# UFS0_COMMON_0_P2A_WRAP_CFG_VBP_UFSHCI register map
Vendor: Texas Instruments
Registers are 32-bit, read-write, reset 0x0 unless marked. A register's access mark holds for its fields unless they carry their own. Offsets are as the file gives them; [hi:lo] are bit positions; lines under a group give offsets from that group; {n}, {i} and the like mark numbered series; 'fields as' and 'values as' point back to an identical list.

## UFS0_COMMON_0_P2A_WRAP_CFG_VBP_UFSHCI (part 2 of 2)
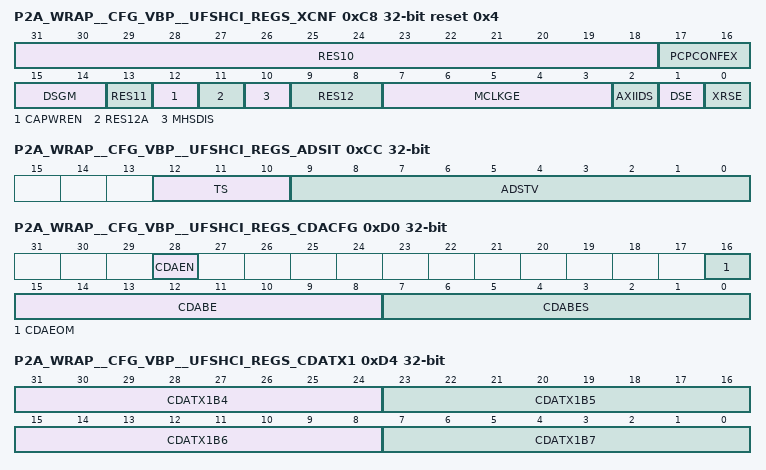
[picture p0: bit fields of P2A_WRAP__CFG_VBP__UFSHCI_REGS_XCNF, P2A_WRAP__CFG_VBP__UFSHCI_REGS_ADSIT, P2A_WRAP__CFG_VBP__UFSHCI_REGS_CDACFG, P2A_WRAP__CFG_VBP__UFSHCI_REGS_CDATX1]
0xC8 P2A_WRAP__CFG_VBP__UFSHCI_REGS_XCNF access per field reset 0x4
  [31:18] RES10 ro — RES - Reserved
  [17:16] PCPCONFEX rw — PCPCONFEX - Peer C-Port Configuration Extended These bits configure the peer C-Port configuration. 00b - Standard, no action 01b - Standard, no action 10b - Peer C-Port 0 connection state polling 11b - Peer configuration by UFSHCI
  [15:14] DSGM rw — DSGM - Deep-Sleep Generation Mode These bits define, how and when the {MK2,MK2} pattern is sent by the UFS host controller. 00b - Disabled. Regardless of the XCNF.DSE setting, no {MK2,MK2} pattern is generated. 01b - Use XCNF.DSE bit, static assignment. With this setting, the {MK2,MK2} pattern will be generated every time the TX path at the end of every data traffic, e.g. when the data path has no more data to send. Although this setting will generate the required {MK2,MK2} sequence, the {MK2,MK2} pattern is generated too often and unnecessary guard time delays appear in the system. 10b - Use ADSIT and XCNF.DSE With this setting, the {MK2,MK2} pattern will be send after the auto-deep-sleep counter is expired. The method how the {MK2,MK2} pattern is sent, is via 0-byte payload, e.g. at the end of the data transfer. This method also works when the device has not send a {MK2,MK2} with the final AFC. 11b - Use ADSIT and XCNF.DSE With this setting the, {MK2,MK2} pattern will be send after the auto-deep-sleep counter is expired. The method how the {MK2,MK2} pattern is send is via assertion of the UniPro burst signal, e.g. filler pattern. This method will not work if the device has not sent the {MK2,MK2} pattern yet, as there are AFCs going back as a response to a filler sequence. The deep-sleep mode defines the way, how and when the {MK2,MK2} pattern will be generated. The LA_TxLastMessage setting is taken from the XCNF.DSE bit.
  [13] RES11 ro — RES - Reserved
  [12] CAPWREN rw — CAPWREN - Capability Register Write Enable Setting this bit, will change the JEDEC capability register to be writable. 0h - Default behavior. Capability register is read only. 1h - Capability register can be written. This function can be used to verify different driver behavior. This is typically a debug feature and the register is most likely fixed in a production release.
  [11] RES12A ro — RES - Reserved
  [10] MHSDIS rw
  [9:8] RES12 ro — RES - Reserved
  [7:3] MCLKGE rw — MCLKGE - Module Clock Gating Enable These bits enable or disable the hierarchical clock gating per module. //[8] - UM support module clock gating enable/disable. [7] - OCS status word write module clock gating enable/disable. [6] - Read DMA data path module clock gating enable/disable. [5] - Write DMA data path module clock gating enable/disable. [4] - Command processing module clock gating enable/disable. [3] - Command fetching module clock gating enable/disable. All enable/disable bits follow the logic: 0b - Hierarchical clock gating enabled. 1b - Hierarchical clock gating disabled. The clocks are disabled at the individual module or function hierarchical boundary, based on internal status information, e.g. the 'OCS status word write module' will not be clocked whenever there is no status word to be written.
  [2] AXIIDS rw — AXIIDS - AXI ID support 0b - AXI ID support is disabled. 1b - AXI ID support is enabled.
  [1] DSE rw — DSE - Deep Sleep Enable This bit enables the extended {MK2,MK2} pattern generation. This extension is a MIPI UniPro features which allows saving power in the MPHY by turning off part of the MPHYs RX/TX logic - assuming that host and device are supporting deep-sleep. This happens transparent from the rest of the UFS system - unlike hibernate enter/exit which requires either host controller or software interaction. Internally, this bit is connected to the LA_TxLastMessage port of the UniPro IP, thus it allows for a static setting of the port. 0b - LA_LastMessage is de-asserted. No last message is generated based on the setting in the XCNF register fields. Sending a {MK2,MK2} pattern is still possible by using the MMTR register. 1b - LA_LastMessage is asserted. The {MK2,MK2} pattern is sent in the mode defined in the XCNF.DSGM field. Setting this bit to '0x1' and XCNF.DSGM to '0x01' will always send a {MK2,MK2} pattern after the data transmission is complete. Depending on the traffic pattern, this may introduce additional guard time delay on the link.
  [0] XRSE rw — XRSE - Extended Register Space Enable This bit enables the extended register space. This register space is located directly on top of the JEDEC defined UFSHCI register addresses. 0b - Extended Register Space not enabled. 1b - Extended Register Space enabled. Before enabling the pseudo error register space, the XASB.XDP register field has to be configured with the correct base address.
0xCC P2A_WRAP__CFG_VBP__UFSHCI_REGS_ADSIT
  [12:10] TS — TS - Time Scale Multiply value to increase count time 000: Value times 1 us 001: Value times 10 us 010: Value times 100 us 011: Value times 1 ms 100: Value times 10 ms 101: Value times 100 ms 110-111: Reserved.
  [9:0] ADSTV — ADSTV - Auto-Deep-Sleep Idle Timer Value This is the time that UFS subsystem must be idle before the UFS host controller may put the UFS link into deep-sleep state autonomously. The idle timer value is multiplied by the indicated timer scale to yield an absolute timer value. The idle timer starts decrement when all of the following conditions are satisfied: - UTRLDBR='0' - UTMRLDBR='0' - No UIC commanding is outstanding The idle timer shall continue decrement until it reaches zero or it is stopped as result of software access to one of host controller interface registers. When idle timer changes a non-zero to zero, the host controller shall put the UFS link into deep-sleep state. The host controller reloads this value each time the UFS link transitions out of the deep-sleep state. Software writes '0' to disable Auto-Deep-Sleep Idle Timer. Any non-zero value will enable Auto-Deep-Sleep idle timer. The minimum counter value is 1us, the maximum counter value is 102.3s. The Auto-Deep-Sleep idle timer will trigger the generation of the {MK2,MK2} transfer. The method, how the {MK2,MK2} pattern is generated is defined in the XCFN.DSGM register: 00b - Disabled. Setting this value will suppress any {MK2,MK2} pattern generation. Expiration of the auto-deep-sleep timer will have no effect. 01b - Use XCNF.DSE bit, static assignment. Expiration of the auto-deep-sleep timer will have no effect, e.g. there will be no activity. 10b - Use ADSIT. With this setting the {MK2,MK2} pattern will be send after the auto-deep-sleep counter has expired. The method how the {MK2,MK2} pattern is send is via 0-byte payload. 11b - Use ADSIT. With this setting the {MK2,MK2} pattern will be send after the auto-deep-sleep counter has expired. The method how the {MK2,MK2} pattern is send is via assertion of the UniPro burst signal.
0xD0 P2A_WRAP__CFG_VBP__UFSHCI_REGS_CDACFG access per field
  [28] CDAEN rw — CDAEN - C-Port Direct Access Enable This bit enables the direct access feature.
  [16] CDAEOM rw — CDAEOM - C-Port Direct Access End of message indicator. Setting this bit forces the Host UniPro adapter to flush the message.
  [15:8] CDABE rw — CDABE - C-Port Direct Access Byte Enables Byte enables for the transmit data. Bit 15: CDATX2B0 Bit 14: CDATX2B1 Bit 13: CDATX2B2 Bit 12: CDATX2B3 Bit 11: CDATX1B4 Bit 10: CDATX1B5 Bit 9: CDATX1B6 Bit 8: CDATX1B7 If not all bytes carry valid payload, valid bytes shall use the lower CDATXx byte fields. Example [Supported]: CDABE = FCh Example [Not supported]: CDABE = CFh
  [7:0] CDABES ro — CDABES - C-Port Direct Access Shadow Byte Enables Reserved for 64-bit data bus setup. In a 128bit system setup this field specifies the byte enables for the 64bit shadow register. Byte enables for the transmit data. Bit 15: CDATX2B0 shadow Bit 14: CDATX2B1 shadow Bit 13: CDATX2B2 shadow Bit 12: CDATX2B3 shadow Bit 11: CDATX1B4 shadow Bit 10: CDATX1B5 shadow Bit 9: CDATX1B6 shadow Bit 8: CDATX1B7 shadow If not all bytes carry valid payload, valid bytes shall use the lower CDATXx byte fields.
0xD4 P2A_WRAP__CFG_VBP__UFSHCI_REGS_CDATX1
  [63-8n:56-8n] CDATX1B{n} (n=4..7) — CDATX1B{n} - Write Data Byte {n}
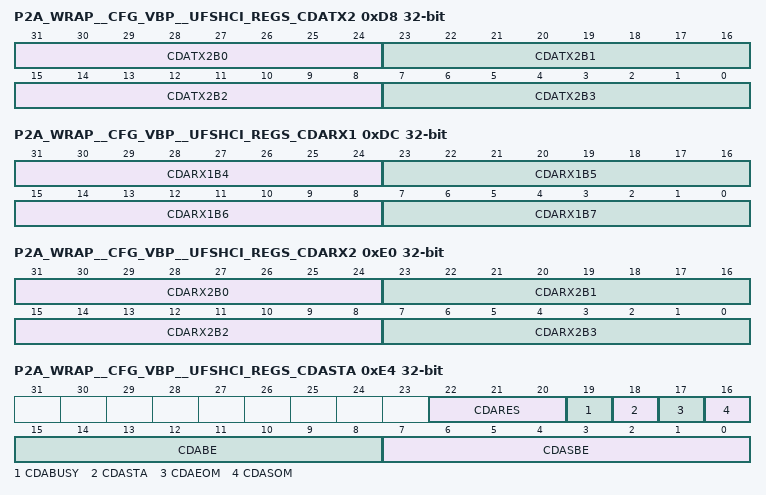
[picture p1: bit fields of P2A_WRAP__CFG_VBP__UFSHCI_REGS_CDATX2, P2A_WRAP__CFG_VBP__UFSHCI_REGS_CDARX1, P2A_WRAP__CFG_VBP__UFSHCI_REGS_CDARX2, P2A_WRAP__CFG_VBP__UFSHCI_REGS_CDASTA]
0xD8 P2A_WRAP__CFG_VBP__UFSHCI_REGS_CDATX2
  [31-8n:24-8n] CDATX2B{n} (n=0..3) — CDATX2B{n} - Write Data Byte {n}
0xDC P2A_WRAP__CFG_VBP__UFSHCI_REGS_CDARX1 ro
  [63-8n:56-8n] CDARX1B{n} (n=4..7) — CDARX1B{n} - Read Data Byte {n}
0xE0 P2A_WRAP__CFG_VBP__UFSHCI_REGS_CDARX2 ro
  [31-8n:24-8n] CDARX2B{n} (n=0..3) — CDARX2B{n} - Read Data Byte {n}
0xE4 P2A_WRAP__CFG_VBP__UFSHCI_REGS_CDASTA ro
  [22:20] CDARES — CDARES - C-Port Direct Access Result Transmit result code. This field stores the result information from the last transmit operation. This field carries the TxResultCode from the UIC layer. It becomes valid one HClk cycle after the transfer has been completed. 0: Access successful 1: local CPort is unconnected 2: reserved, unused for data transmission 3: local CPort is not available 6: peer device does not support selected TC 7: Message of 0 size rejected [EOM false]
  [19] CDABUSY — CDABUSY - C-Port Direct Access Busy This bit indicates whether the C-Port is busy. The software shall poll this bit and make sure that the C-Port is available prior to any write access to the CDATX1 or CDATX2 registers. During data transmission, this bit is set to 1 until the transfer has been completed. 0: C-Port available 1: C-Port busy
  [18] CDASTA — CDASTA - C-Port Direct Access Status The status bit indicates if there is new data in the buffer.
  [17] CDAEOM — CDAEOM - C-Port Direct Access EOM End of message indicator.
  [16] CDASOM — CDASOM - C-Port Direct Access SOM Start of message indicator
  [15:8] CDABE — CDABE - C-Port Direct Access Byte Enable Byte enable settings for the received data.
  [7:0] CDASBE — CDASBE - C-Port Direct Access Shadow Byte Enable Reserved in a 64 system bus configuration. In a 128 system bus configuration this field contains the byte enable settings for the received data in the shadow register.
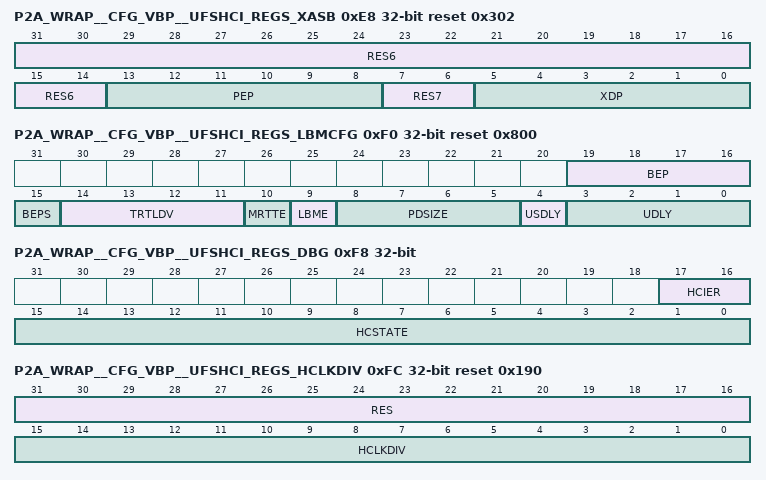
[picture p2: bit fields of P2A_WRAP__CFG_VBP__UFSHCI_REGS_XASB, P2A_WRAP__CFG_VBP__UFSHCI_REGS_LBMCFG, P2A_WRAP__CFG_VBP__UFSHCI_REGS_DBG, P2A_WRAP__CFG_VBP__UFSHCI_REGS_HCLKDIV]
0xE8 P2A_WRAP__CFG_VBP__UFSHCI_REGS_XASB access per field reset 0x302
  [31:14] RES6 ro — RES - Reserved
  [13:8] PEP rw — PEP - Pseudo Error Page This address defines define the page address for the pseudo error configuration and control register in units of 1Kbytes. Minimum value is 01h to avoid collisions with MMIO page. Available Register: - All pseudo error register The page address is only valid [and will be used for address selection] when the XCNF.PERSEN is set to '1'.
  [7:6] RES7 ro — RES - Reserved
  [5:0] XDP rw — XDP - Extended Debug Page This address defines the page address of the extended debugging information. Available registers: - EXTREG1 - ... - EXTREG8 - UFSDC - UPSTAT - URW - URS - CDC - RTDDC - TPTXF - TPRXF - IUE - MMTR The page address is only valid [and will be used for address selection] when the XCNF.XRSE is set to '1'. All accesses to the Extended Debug Page will not wake up the host controller from auto-hibernate or auto deep-sleep.
0xF0 P2A_WRAP__CFG_VBP__UFSHCI_REGS_LBMCFG reset 0x800
  [19:16] BEP — BEP - Byte Enable Pattern This field defines the number of valid byte enables. The byte enables are filled up from MSB to LSB. This is a test mode only. For normal operation this field should be kept at the default value. 1 - Byte 7 enabled 2 - Byte 7:6 enabled 3 - Byte 7:5 enabled 4 - Byte 7:4 enabled 5 - Byte 7:3 enabled 6 - Byte 7:2 enabled 7 - Byte 7:1 enabled Others - Byte 7:0 enabled The field width is 4 bit in case the IP is configured for 64bit system data bus width and 5bit for a 128bit configuration.
  [15] BEPS — BEPS - Byte Enable Pattern Selection This bit selects between a random byte enable pattern and a fixed byte enable pattern in 'read only' mode [LUN 0]. In write only and 'loopback mode' this field is ignored. The fixed byte enable pattern is taken from the BEP field of the LBMCFG register. This is a test mode only. For normal operation this field should be kept at the default value. 0b - Fixed byte enable pattern taken from BEP field 1b - Random byte enable pattern
  [14:11] TRTLDV — TRTLDV - Throttle Divide Since the bandwidth on the system bus may be much higher than actually supported by the UniPro link, this value allows to throttle the bandwidth in order to better mimic a real UFS Device. However, by this, some inaccuracy to the performance measurement will be introduced since the time to fill or empty the system bus buffer changes, which in turn has influence on the rate in which system bus requests to the bus fabric can be issued. Value 0: Reserved Value 1-15: Divide the frequency in which data is requested from the system bus RX buffer and/or stored into the system bus TX buffer.
  [10] MRTTE — MRTTE - Multi RTT Enable This bit enables the multiple RTT feature. Here multiple RTT may be submitted by the loopback logic. This feature tests the performance of back to back DATAOUT UPIUs. It provides feedback about the capabilities of the host controller RTT management capabilities. If DATAOUT UPIUs exceed a certain size [size depends on the access latency to the system memory], a second outstanding RTT may help reducing the latency between two consecutive DATAOUT UPIUs. This feature requires that a second RTT is send to the host controller ahead of time. This enables the data management to fetch the data for the second RTT, while the data for the first RTT is still being sent over the UniPro link. It should be noted, that data transfer is in-order, and thus sending of data which belongs to the second RTT will not start before the first RTT is completely handled. The maximum number of outstanding RTT is two. Once the DATAOUT UPIUs for both RTTs have been transmitted, the next RTTs [2 or less] will be issued until all data that have been requested by the SCSI command were transferred. 0: Only one RTT 1: Up to two outstanding RTTs
  [9] LBME — LBME - Loopback Enable bit Setting this bit decouples the UniPro layer from the host controller logic and switches the input data stream to take packets from the loopback logic. If LBME=0, the UPIU loopback circuit is in reset. If LBME=1, it is assured that no interaction with an attached UFS Device takes place.
  [8:5] PDSIZE — PDSIZE - Data Size This value is a 4-bit field and defines the amount of the data that will be requested by the RTT. This mimics the ability of the UFS Device to limit the size of a DATAOUT UPIU. In loopback mode, PDSIZE defines the size of DATAOUT and DATAIN UPIUs. The field should be interpreted as the exponent of the function pow[2, PDSIZE+1]. PDSIZE values from 3h to Eh are supported. This allows sizes from 16 to 32768 bytes.
  [4] USDLY — USDLY - UPIU Source Delay This one-bit field defines whether there is a delay before every RTTs or DATAIN packet or just before the first one.
  [3:0] UDLY — UDLY - UPIU Delay This value is a 4-bit field and defines the delay [in clock cycles] from receiving the command till the response is send back to the host controller. The response could either be an RTT UPIU or a DATAIN UPIU. This allows the host controller to fetch the required PRD entries an immediately continue with processing the RTT or DATAIN UPIU. The field should be interpreted as the exponent of the function pow[2, UDLY+4]. This allows delays from 16 to 524288 clock cycles which is approx. from 80ns to 2.6ms with a 200MHz clock. Those large numbers mimic the real behaviour of current devices. A value of zero disables this feature, means no delay. Whether or not this delay is used for every return packet or just for the first one is controlled by the USDLY field.
0xF4 P2A_WRAP__CFG_VBP__UFSHCI_REGS_LBMSTA ro
  [0] ERR — ERR - Error Indicator Indicates that there is general error. ERR=1 indicates that an error condition has been detected. Once an error condition has been detected, the UPIU loopback circuit needs to be disabled and enabled again via the LBME bit. By this, the ERR register is cleared. Detectable error conditions: Command sent to unsupported LUN Unsupported command [Transaction Type]
0xF8 P2A_WRAP__CFG_VBP__UFSHCI_REGS_DBG ro
  [17:16] HCIER — HCIER - Host Controller Internal Error Register This register displays host controller internal errors which are not covered by the JEDEC official errors reported back via the OCS value. 0h: No error occurred 1h: No valid TAG/LUN combination found. The UPIU with no valid TAG/LUN combination will be silently discarded. 2h: No valid TAG/LUN/IID combination found. The UPIU with no valid TAG/LUN/IID combination will be silently discarded.
  [15:0] HCSTATE — HCSTATE - Host Controller State Register These bits indicate the internal state of the host controller. The value is used for internal use only. 0h: No error occurred value: An error occurred. The meaning of the value is not disclosed.
0xFC P2A_WRAP__CFG_VBP__UFSHCI_REGS_HCLKDIV access per field reset 0x190
  [31:16] RES ro — RES - Reserved
  [15:0] HCLKDIV rw — HCLKDIV - HClock Divide HCLKDIV = HCLKFrequency [MHz] The default value of the HCLKDIV register assumes a HClk frequency of 400MHz. The default value may be adjusted during implementation by changing the P_P_CLKDIV parameter.
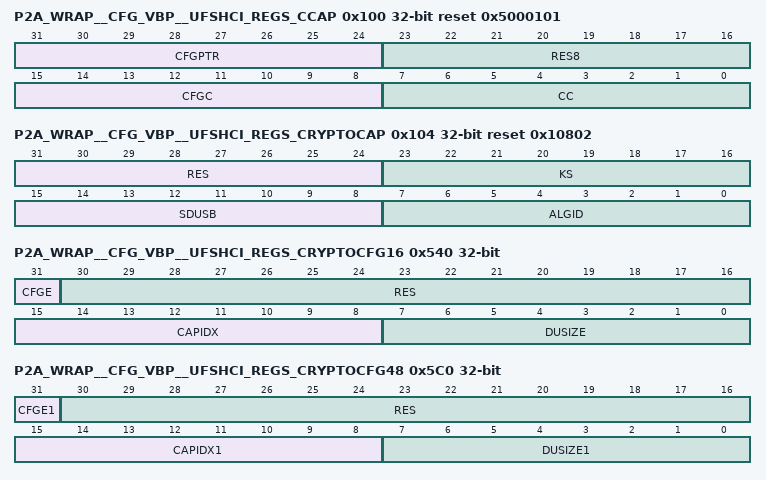
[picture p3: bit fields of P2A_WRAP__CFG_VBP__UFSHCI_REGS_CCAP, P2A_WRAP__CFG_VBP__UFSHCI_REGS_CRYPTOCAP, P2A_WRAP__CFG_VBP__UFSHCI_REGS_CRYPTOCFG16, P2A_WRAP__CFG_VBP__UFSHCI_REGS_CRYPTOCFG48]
0x100 P2A_WRAP__CFG_VBP__UFSHCI_REGS_CCAP ro reset 0x5000101
  [31:24] CFGPTR — CFGPTR - Configuration Array Pointer An offset pointer to the base of the Configuration Array [X-CRYPTOCFG registers], in 256B units. CFGPTR value shall be larger than 04h, so it does not conflict with a maximum size X-CRYPTOCAP array. The address for entry x of the X-CRYPTOCFG array is calculated as follows: ADDR [X-CRYPTOCFG] = CFGPTR*100h + x*80h, with x in [0..CCAP.CFGC] and x derived from UTRD.CCI field.
  [23:16] RES8 — RES - Reserved
  [15:8] CFGC — CFGC - Configuration Count The maximum number of configurations supported by the host controller. The actual number of configurations is equal to [CFGC+1]. The minimum number of configurations supported is 1 [CFGC=00h]. The maximum number of configurations supported is 256 [CFGC=FFh].
  [7:0] CC — CC - Crypto Capabilities The number of crypto capabilities that the host controller provides. The values allowed are between 1 and 255[the limit on the number of crypto capabilities].
0x104 P2A_WRAP__CFG_VBP__UFSHCI_REGS_CRYPTOCAP ro reset 0x10802
  [31:24] RES — RES - Reserved
  [23:16] KS — KS - Key Size Specifies the Key Size in bits used by this algorithm: 00h: Reserved 01h: 128bits 02h: 192bits [not supported] 03h: 256bits [not supported] 04h: 512bits [not supported] 05h-FFh: Reserved
  [15:8] SDUSB — SDUSB - Supported Data Unit Size Bitmask Specifies the data unit sizes supported by the capability, in bitmask encoding. When bit j in the field [j=0...7] is set, data unit size of 512*2^j bytes is supported. Supported values: 512B [j=0] through 64KB [j=7]. One bit or more in this field may be set. For example, if sizes 1KB, 4KB, and 16KB are supported by the capability, then SDUSB=00101010b [=2Ah].
  [7:0] ALGID — ALGID - Algorithm Identification code of the crypto algorithm according to the following table value: 00h: AES-XTS [not supported] 01h: Bitlocker-AES-CBC [not supported] 02h: AES-ECB 03h: ESSIV AES-CBC [not supported] 04h-7Fh: Reserved 80h-FFh: Vendor specific This register can only be accessed when the encryption feature is implemented [CAP.CS=1].
{0x500+4i} P2A_WRAP__CFG_VBP__UFSHCI_REGS_CRYPTOCFG{i} wo (i=0..3)
  [31:0] CRYPTOKEY{i} — CRYPTOKEY{i} - Crypto Key {i} Specifies the key to be used for this configuration. The specific key layout is defined according to the key size and algorithm specified in the Crypto Capability with index value specified in CAPIDX. When configuring CRYPTOKEY field software shall write the entire key sequentially, in one atomic set of operations. To regions of CRYPTOKEY which are unused, according to key size and algorithm selection, software shall write zeros.
0x540 P2A_WRAP__CFG_VBP__UFSHCI_REGS_CRYPTOCFG16 access per field
  [31] CFGE rw — CFGE - Configuration Enable This field is used by software to enable/disable a Crypto Configuration usage by software 0b: Configuration Disabled. Transaction using this Crypto Configuration in the UTRD.CCI field shall be terminated with error by host controller [OCS=INVALID_CRYPTO_CONFIG] 1b: Configuration Enabled. Transaction using this Configuration in the UTRD.CCI field can be executed.
  [30:16] RES ro — RES - Reserved
  [15:8] CAPIDX rw — CAPIDX - Crypto Capability Index Specifies the index of the Crypto Capability to be used for this configuration. Values allowed are between 0 and CCAP.CC-1. There is no hardware range check implemented.
  [7:0] DUSIZE rw — DUSIZE - Data Unit Size Size of data unit used with this configuration, one-hot encoded, analogous to bitmask used in CRYPTOCAP.SDUSB field. When bit j in this field [j=0...7] is set, a data unit size of 512*2^j bytes is selected. Bit j shall only be set if the same bit is also set in the SDUSB field og the capability referenced in CAPIDX field. There is no hardware check for consistency between CRYPTOCFG.DUSIZE and CRYPTOCAP.SDUSB.
0x544 P2A_WRAP__CFG_VBP__UFSHCI_REGS_CRYPTOCFG17
  [31:16] VSB — VSB - Vendor-Specific Bits This field is used by software to enable host-features associated with the Crypto Configuration.
{0x500+4i} P2A_WRAP__CFG_VBP__UFSHCI_REGS_CRYPTOCFG{i} wo (i=32..35)
  [31:0] CRYPTOKEY{i} — CRYPTOKEY{i} - Crypto Key {i-32} for second crypto configuration Specifies the key to be used for this configuration. The specific key layout is defined according to the key size and algorithm specified in the Crypto Capability with index value specified in CAPIDX. When configuring CRYPTOKEY field software shall write the entire key sequentially, in one atomic set of operations. To regions of CRYPTOKEY which are unused, according to key size and algorithm selection, software shall write zeros.
0x5C0 P2A_WRAP__CFG_VBP__UFSHCI_REGS_CRYPTOCFG48 access per field
  [31] CFGE1 rw — CFGE1 - Configuration Enable for second crypto configuration This field is used by software to enable/disable a Crypto Configuration usage by software 0b: Configuration Disabled. Transaction using this Crypto Configuration in the UTRD.CCI field shall be terminated with error by host controller [OCS=INVALID_CRYPTO_CONFIG] 1b: Configuration Enabled. Transaction using this Configuration in the UTRD.CCI field can be executed.
  [30:16] RES ro — RES - Reserved
  [15:8] CAPIDX1 rw — CAPIDX1 - Crypto Capability Index for second crypto configuration Specifies the index of the Crypto Capability to be used for this configuration. Values allowed are between 0 and CCAP.CC-1. There is no hardware range check implemented.
  [7:0] DUSIZE1 rw — DUSIZE1 - Data Unit Size for second crypto configuration Size of data unit used with this configuration, one-hot encoded, analogous to bitmask used in CRYPTOCAP.SDUSB field. When bit j in this field [j=0...7] is set, a data unit size of 512*2^j bytes is selected. Bit j shall only be set if the same bit is also set in the SDUSB field og the capability referenced in CAPIDX field. There is no hardware check for consistency between CRYPTOCFG.DUSIZE and CRYPTOCAP.SDUSB.
0x5C4 P2A_WRAP__CFG_VBP__UFSHCI_REGS_CRYPTOCFG49
  [31:16] VSB1 — VSB1 - Vendor-Specific Bits for second crypto configuration This field is used by software to enable host-features associated with the Crypto Configuration.
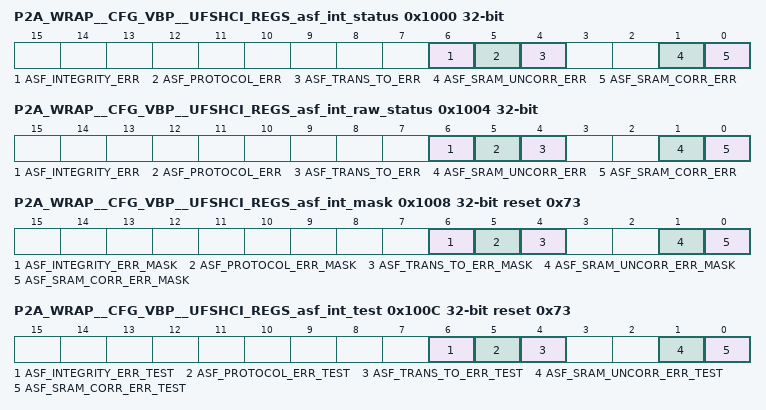
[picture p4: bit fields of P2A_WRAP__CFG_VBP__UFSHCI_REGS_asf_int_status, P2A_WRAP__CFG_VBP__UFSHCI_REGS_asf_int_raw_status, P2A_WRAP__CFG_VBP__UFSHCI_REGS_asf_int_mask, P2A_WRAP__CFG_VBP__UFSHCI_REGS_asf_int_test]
0x1000 P2A_WRAP__CFG_VBP__UFSHCI_REGS_asf_int_status access not given
  [6] ASF_INTEGRITY_ERR — Integrity error interrupt (access R/W1TC)
  [5] ASF_PROTOCOL_ERR — Protocol error interrupt (access R/W1TC)
  [4] ASF_TRANS_TO_ERR — Transaction timeouts error interrupt (access R/W1TC)
  [1] ASF_SRAM_UNCORR_ERR — SRAM uncorrectable error interrupt (access R/W1TC)
  [0] ASF_SRAM_CORR_ERR — SRAM correctable error interrupt (access R/W1TC)
0x1004 P2A_WRAP__CFG_VBP__UFSHCI_REGS_asf_int_raw_status access not given
  fields as P2A_WRAP__CFG_VBP__UFSHCI_REGS_asf_int_status
0x1008 P2A_WRAP__CFG_VBP__UFSHCI_REGS_asf_int_mask access not given reset 0x73
  [6] ASF_INTEGRITY_ERR_MASK rw — Mask bit for integrity error interrupt
  [5] ASF_PROTOCOL_ERR_MASK rw — Mask bit for protocol error interrupt.
  [4] ASF_TRANS_TO_ERR_MASK rw — Mask bit for transaction timeouts error interrupt.
  [1] ASF_SRAM_UNCORR_ERR_MASK rw — Mask bit for SRAM uncorrectable error interrupt.
  [0] ASF_SRAM_CORR_ERR_MASK rw — Mask bit for SRAM correctable error interrupt.
0x100C P2A_WRAP__CFG_VBP__UFSHCI_REGS_asf_int_test access not given reset 0x73
  [6] ASF_INTEGRITY_ERR_TEST wo — Test bit for integrity error interrupt
  [5] ASF_PROTOCOL_ERR_TEST wo — Test bit for protocol error interrupt.
  [4] ASF_TRANS_TO_ERR_TEST wo — Test bit for transaction timeouts error interrupt.
  [1] ASF_SRAM_UNCORR_ERR_TEST wo — Test bit for SRAM uncorrectable error interrupt.
  [0] ASF_SRAM_CORR_ERR_TEST wo — Test bit for SRAM correctable error interrupt.
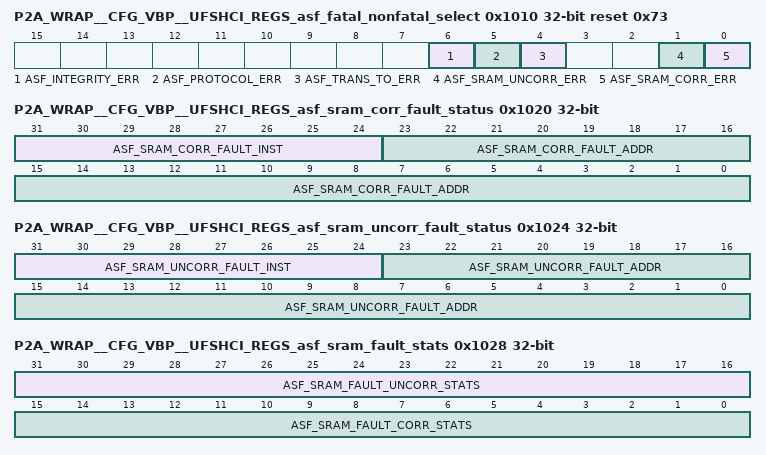
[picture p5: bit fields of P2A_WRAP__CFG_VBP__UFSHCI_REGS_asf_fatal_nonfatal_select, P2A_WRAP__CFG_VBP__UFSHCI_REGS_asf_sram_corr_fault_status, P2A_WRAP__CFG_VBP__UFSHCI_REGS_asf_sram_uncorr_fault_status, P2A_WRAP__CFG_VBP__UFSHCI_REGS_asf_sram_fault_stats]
0x1010 P2A_WRAP__CFG_VBP__UFSHCI_REGS_asf_fatal_nonfatal_select access not given reset 0x73
  [6] ASF_INTEGRITY_ERR rw — Enable integrity error interrupt as fatal
  [5] ASF_PROTOCOL_ERR rw — Enable protocol error interrupt as fatal.
  [4] ASF_TRANS_TO_ERR rw — Enable transaction timeouts error interrupt as fatal.
  [1] ASF_SRAM_UNCORR_ERR rw — Enable SRAM uncorrectable error interrupt as fatal.
  [0] ASF_SRAM_CORR_ERR rw — Enable SRAM correctable error interrupt as fatal.
0x1020 P2A_WRAP__CFG_VBP__UFSHCI_REGS_asf_sram_corr_fault_status ro
  [31:24] ASF_SRAM_CORR_FAULT_INST — This encoding indicates which SRAM Instance has a Correctable Fault. The encoding of the SRAM is as follow: Decimal Encoding - Instance Type - Description - Module Name 0 - RDF - Read Data FIFO - RDP 1 - RDC - Read Data Path Control Unit - RDC 2 - WDF - Write Data FIFO - WDP 3 - WDCF - Write Data Path Control FIFO - WDC 4 - WDC - Write Data Path Control Unit - WDC 5 - RTT - WDC RTT command stack - WDC 6 - WDCM - WDC task management command stack - WDC 7 - CIP - Command Interface Port - CIP 8 - CMU1 - Command Memmory Unit - CMU 9 - CMU2 - Command Memmory Unit - CMU 10 - CMU3 - Command Memmory Unit - CMU 11 - CMU4 - Command Memmory Unit - CMU 12 - CMU5 - Command Memmory Unit - CMU 13 - CMU6 - Command Memmory Unit - CMU 14 - CMU7 - Command Memmory Unit - CMU 15 - TMU - Task Management Unit - TMU 16 - UniPro L2RX - UniPro - L2TX 17* - UniPro L2TX - UniPro - L2RX 18* - UniPro L2TX - UniPro - L2RX 19 - CCI - Crypto Configuration Index - AES 20 - ID - Stores the identifiers for the selected Doorbell Register slot numbers - AES *NOTE: ID17 used for uncorrectable errors ID18 used for correctable errors.
  [23:0] ASF_SRAM_CORR_FAULT_ADDR — This indicates the address where the Correctable fault was observed.
0x1024 P2A_WRAP__CFG_VBP__UFSHCI_REGS_asf_sram_uncorr_fault_status ro
  [31:24] ASF_SRAM_UNCORR_FAULT_INST — This encoding indicates which SRAM Instance has a UnCorrectable Fault. The encoding of the SRAM is as follow: Decimal Encoding - Instance Type - Description - Module Name 0 - RDF - Read Data FIFO - RDP 1 - RDC - Read Data Path Control Unit - RDC 2 - WDF - Write Data FIFO - WDP 3 - WDCF - Write Data Path Control FIFO - WDC 4 - WDC - Write Data Path Control Unit - WDC 5 - RTT - WDC RTT command stack - WDC 6 - WDCM - WDC task management command stack - WDC 7 - CIP - Command Interface Port - CIP 8 - CMU1 - Command Memmory Unit - CMU 9 - CMU2 - Command Memmory Unit - CMU 10 - CMU3 - Command Memmory Unit - CMU 11 - CMU4 - Command Memmory Unit - CMU 12 - CMU5 - Command Memmory Unit - CMU 13 - CMU6 - Command Memmory Unit - CMU 14 - CMU7 - Command Memmory Unit - CMU 15 - TMU - Task Management Unit - TMU 16 - UniPro L2RX - UniPro - L2TX 17* - UniPro L2TX - UniPro - L2RX 18* - UniPro L2TX - UniPro - L2RX 19 - CCI - Crypto Configuration Index - AES 20 - ID - Stores the identifiers for the selected Doorbell Register slot numbers - AES *NOTE: ID17 used for uncorrectable errors ID18 used for correctable errors.
  [23:0] ASF_SRAM_UNCORR_FAULT_ADDR — This indicates the address where the UnCorrectable fault was observed.
0x1028 P2A_WRAP__CFG_VBP__UFSHCI_REGS_asf_sram_fault_stats access not given
  [31:16] ASF_SRAM_FAULT_UNCORR_STATS — Count of number of uncorrectable errors if implemented. Count value will saturate at 0xffff. (access R/W1TC)
  [15:0] ASF_SRAM_FAULT_CORR_STATS — Count of number of correctable errors if implemented. Count value will saturate at 0xffff. (access R/W1TC)
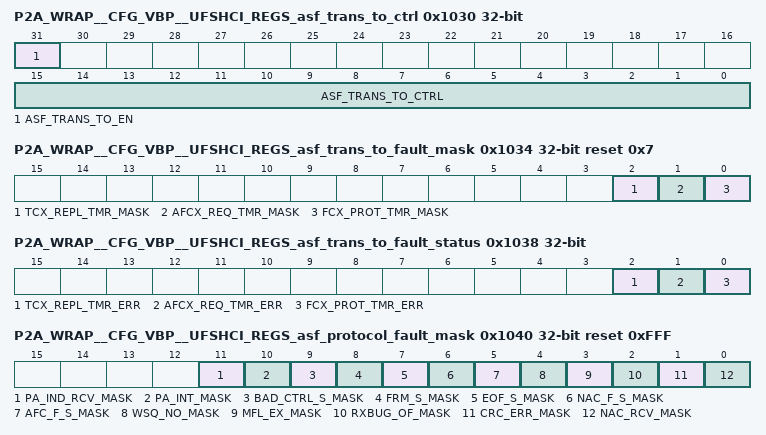
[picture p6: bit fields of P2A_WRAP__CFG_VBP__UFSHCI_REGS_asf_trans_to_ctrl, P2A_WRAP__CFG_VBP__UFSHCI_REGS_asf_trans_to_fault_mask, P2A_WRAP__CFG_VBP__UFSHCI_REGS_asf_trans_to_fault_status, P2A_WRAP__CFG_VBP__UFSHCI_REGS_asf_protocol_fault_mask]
0x1030 P2A_WRAP__CFG_VBP__UFSHCI_REGS_asf_trans_to_ctrl access not given
  [31] ASF_TRANS_TO_EN rw — Enable transaction timeout monitoring.
  [15:0] ASF_TRANS_TO_CTRL rw — Reserved.
0x1034 P2A_WRAP__CFG_VBP__UFSHCI_REGS_asf_trans_to_fault_mask access not given reset 0x7
  [2] TCX_REPL_TMR_MASK rw — TCx_REPLAY_TIMER_EXPIRED mask.
  [1] AFCX_REQ_TMR_MASK rw — AFCx_REQUEST_TIMER_EXPIRED mask.
  [0] FCX_PROT_TMR_MASK rw — FCx_PROTECTION_TIMER_EXPIRED mask.
0x1038 P2A_WRAP__CFG_VBP__UFSHCI_REGS_asf_trans_to_fault_status access not given
  [2] TCX_REPL_TMR_ERR — TCx_REPLAY_TIMER_EXPIRED timeout detected. The replay timer [TCx_REPLAY_TIMER, where x=0 or 1] guards against losing AFC or NAC Frame detection. (access R/W1TC)
  [1] AFCX_REQ_TMR_ERR — AFCx_REQUEST_TIMER_EXPIRED timeout detected. The Frame acknowledge timer [AFCx_REQUEST_TIMER] shall guarantee that the remote transmitter schedules an AFC Frame before the transmitter TCx_REPLAY_TIMER expires. (access R/W1TC)
  [0] FCX_PROT_TMR_ERR — FCx_PROTECTION_TIMER_EXPIRED timeout detected. The FCx_PROTECTION_TIMER id used for protecting against loss of credits due to the loss of the AFCx Frame. (access R/W1TC)
0x1040 P2A_WRAP__CFG_VBP__UFSHCI_REGS_asf_protocol_fault_mask access not given reset 0xFFF
  [11] PA_IND_RCV_MASK rw — When set to 1 disables the UniPro PA_ERROR_IND_RECEIVED.
  [10] PA_INT_MASK rw — When set to 1 disables the UniPro PA_INIT_ERROR.
  [9] BAD_CTRL_S_MASK rw — When set to 1 disables the UniPro BAD_CTRL_SYMBOL_TYPE.
  [8] FRM_S_MASK rw — When set to 1 disables the UniPro FRAME_SYNTAX_ERROR.
  [7] EOF_S_MASK rw — When set to 1 disables the UniPro EOF_SYNTAX_ERROR.
  [6] NAC_F_S_MASK rw — When set to 1 disables the UniPro NAC_FRAME_SYNTAX_ERROR.
  [5] AFC_F_S_MASK rw — When set to 1 disables the UniPro AFC_FRAME_SYNTAX_ERROR.
  [4] WSQ_NO_MASK rw — When set to 1 disables the UniPro WRONG_SEQUENCE_NUMBER.
  [3] MFL_EX_MASK rw — When set to 1 disables the UniPro MAX_FRAME_LENGTH_EXCEEDED.
  [2] RXBUG_OF_MASK rw — When set to 1 disables the UniPro RX_BUFFER_OVERFLOW.
  [1] CRC_ERR_MASK rw — When set to 1 disables the UniPro CRC_ERROR.
  [0] NAC_RCV_MASK rw — When set to 1 disables the UniPro NAC_RECEIVED.
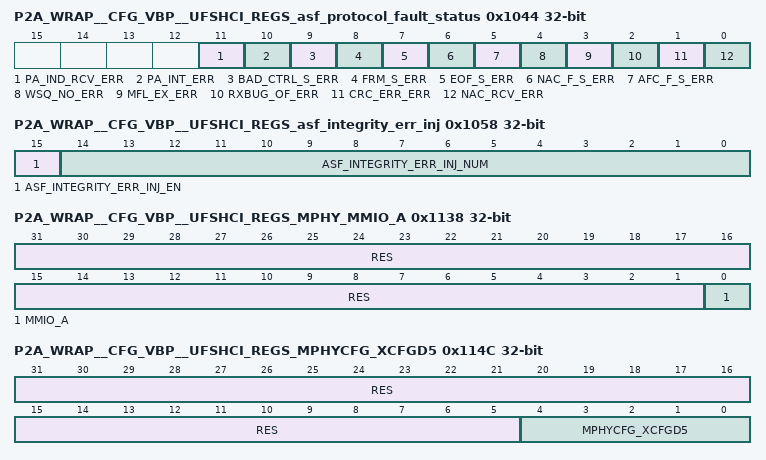
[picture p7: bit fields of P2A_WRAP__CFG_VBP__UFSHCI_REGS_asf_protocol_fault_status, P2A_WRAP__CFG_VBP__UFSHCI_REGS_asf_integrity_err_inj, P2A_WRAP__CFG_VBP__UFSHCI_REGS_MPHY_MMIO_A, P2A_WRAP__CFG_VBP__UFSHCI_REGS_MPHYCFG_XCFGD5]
0x1044 P2A_WRAP__CFG_VBP__UFSHCI_REGS_asf_protocol_fault_status access not given
  [11] PA_IND_RCV_ERR — UniPro PA_ERROR_IND_RECEIVED reported. (access R/W1TC)
  [10] PA_INT_ERR — UniPro PA_INIT_ERROR reported. (access R/W1TC)
  [9] BAD_CTRL_S_ERR — UniPro BAD_CTRL_SYMBOL_TYPE reported. (access R/W1TC)
  [8] FRM_S_ERR — UniPro FRAME_SYNTAX_ERROR reported. (access R/W1TC)
  [7] EOF_S_ERR — UniPro EOF_SYNTAX_ERROR reported. (access R/W1TC)
  [6] NAC_F_S_ERR — UniPro NAC_FRAME_SYNTAX_ERROR reported. (access R/W1TC)
  [5] AFC_F_S_ERR — UniPro AFC_FRAME_SYNTAX_ERROR reported. (access R/W1TC)
  [4] WSQ_NO_ERR — UniPro WRONG_SEQUENCE_NUMBER reported. (access R/W1TC)
  [3] MFL_EX_ERR — UniPro MAX_FRAME_LENGTH_EXCEEDED reported. (access R/W1TC)
  [2] RXBUG_OF_ERR — UniPro RX_BUFFER_OVERFLOW reported. (access R/W1TC)
  [1] CRC_ERR_ERR — UniPro CRC_ERROR reported. (access R/W1TC)
  [0] NAC_RCV_ERR — UniPro NAC_RECEIVED reported. (access R/W1TC)
0x1058 P2A_WRAP__CFG_VBP__UFSHCI_REGS_asf_integrity_err_inj access not given
  [15] ASF_INTEGRITY_ERR_INJ_EN rw — Enable integrity error injection.
  [14:0] ASF_INTEGRITY_ERR_INJ_NUM rw — Bit number at which error is injected. The n is relsted to: a. 0-CRU_OUTS_DATA_WIDTH*: inject error to n bit in comparator in the duplication of the cryptographic core from zero to CRU_OUTS_DATA_WIDTH. Writing bigger value than CRU_OUTS_DATA_WIDTH does not generate integrity fail. * CRU_OUTS_DATA_WIDTH = 1 + 1 + P_T_SDataWdth_6B + P_CP + P_P_ST_3B*16 + 1 + P_P_ST_3B*2 + 1 + [7+1] + 1 + 1 + 1 +P_P_SR_3B*16 + P_P_ST_3B*2 + 1 + 1 + [8+1] + [4+1] + [4+1] + 1 + 1 + [4+1] + [7+1] + [7+1] + 1 + 1 [=238 in asf used configuration].
0x1100 P2A_WRAP__CFG_VBP__UFSHCI_REGS_MAG_NUM ro reset 0x5040A
  [31:0] MAG_NUM — Magic number
0x1104 P2A_WRAP__CFG_VBP__UFSHCI_REGS_MPHYSTAT_XCFGO1 ro
  [31:0] XCFGO1 — XCFGO1 This field is RO - Output debug bits for PHY.
{0x1100+4i} P2A_WRAP__CFG_VBP__UFSHCI_REGS_MPHYSTAT_XCFGO{i} ro (i=2..9)
  [31:0] XCFGO{i} — XCFGO{i} This field is RO - Output debug bits for PHY
0x1128 P2A_WRAP__CFG_VBP__UFSHCI_REGS_MPHY_DEBUG_OUT ro reset 0x60
  [31:0] DEBUG_OUT — DEBUG_OUT - MPHY debug out This field is RO - Vendor Debug Output.
0x112C P2A_WRAP__CFG_VBP__UFSHCI_REGS_MPHY_BIST ro
  [31:0] MPHY_BIST — MPHY_BIST This field is RO - BIST pattern check passed for Lane 0 and 1.
0x1130 P2A_WRAP__CFG_VBP__UFSHCI_REGS_MPHY_SF ro
  [31:0] MPHY_SF — MPHY_SF This field is RO - Safety related.
0x1134 P2A_WRAP__CFG_VBP__UFSHCI_REGS_MPHYSTAT ro
  [31:0] RES — RES - Reserved This field is reserved and RO - MPHY Status.
0x1138 P2A_WRAP__CFG_VBP__UFSHCI_REGS_MPHY_MMIO_A
  [31:1] RES — RES - Reserved This field is reserved and RW - MPHY Configuration.
  [0] MMIO_A — MMIO_A This field is RW - Enable MPHY MMIO access.
{0x1138+4i} P2A_WRAP__CFG_VBP__UFSHCI_REGS_MPHYCFG_XCFGD{i} (i=1..4)
  [31:0] MPHYCFG_XCFGD{i} — MPHYCFG_XCFGD{i} This field is RW - MPHY Configuration for digital part.
0x114C P2A_WRAP__CFG_VBP__UFSHCI_REGS_MPHYCFG_XCFGD5
  [31:5] RES — RES - Reserved This field is reserved and RW - MPHY Configuration.
  [4:0] MPHYCFG_XCFGD5 — MPHYCFG_XCFGD5 This field is RW - MPHY Configuration for digital part.
{0x114C+4i} P2A_WRAP__CFG_VBP__UFSHCI_REGS_MPHYCFG_XCFGA{i} (i=1..13)
  [31:0] MPHYCFG_XCFGA{i} — MPHYCFG_XCFGA{i} This field is RW - MPHY Configuration for analog part.
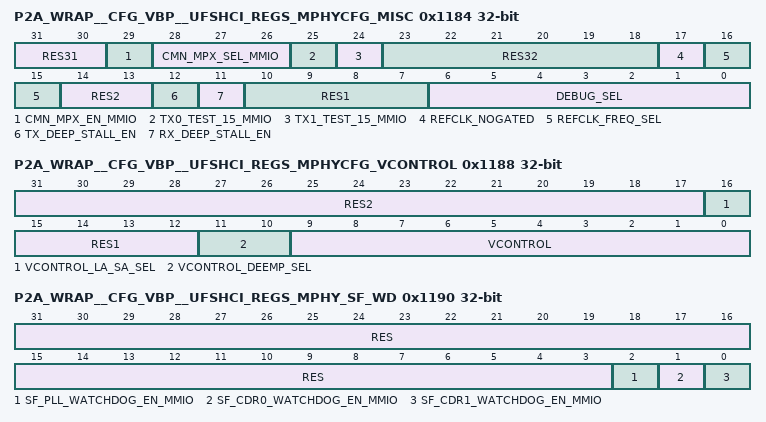
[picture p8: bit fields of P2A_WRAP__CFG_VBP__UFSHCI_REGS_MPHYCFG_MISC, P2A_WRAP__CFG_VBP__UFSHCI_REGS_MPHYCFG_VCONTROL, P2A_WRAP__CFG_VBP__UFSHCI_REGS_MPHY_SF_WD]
0x1184 P2A_WRAP__CFG_VBP__UFSHCI_REGS_MPHYCFG_MISC
  [31:30] RES31 — RES - Reserved This field is reserved and RW - MPHY Configuration.
  [29] CMN_MPX_EN_MMIO — CMN_MPX_EN_mmio Special debug mode for PLL/CDR
  [28:26] CMN_MPX_SEL_MMIO — CMN_MPX_SEL_mmio Special debug mode for PLL/CDR
  [25] TX0_TEST_15_MMIO — TX0_TEST_15_mmio Special debug mode for PLL/CDR
  [24] TX1_TEST_15_MMIO — TX1_TEST_15_mmio Special debug mode for PLL/CDR
  [23:18] RES32 — RES - Reserved This field is reserved and RW - MPHY Configuration.
  [17] REFCLK_NOGATED — REFCLK_NOGATED This field is RW. M31 imprecise reference clocks are not gated in HIBERNATE power state. 0:Gated. 1:Not Gated.
  [16:15] REFCLK_FREQ_SEL — REFCLK_FREQ_SEL This field is RW. Reference clock frequency selection. 00:19.2MHz. 01:26MHz. 10:Reserved. 11:Reserved. There are three conditions to use precise reference clock. a.For PHY normal operation in HOST mode, user should know the frequency of output precise reference clock. b.For LS VCO calibration under VENDOR control mode, user should know the frequency of input precise reference clock from automatic test equipment. The precise reference clock input is from REFCLK_PCS_In port when PHY is in HOST mode, and from REFCLK pin when PHY is in DEVICE mode. c.For PHY normal operation in DEVICE mode, user may NOT know the frequency of input precise reference clock from REFCLK pin. User may set this signal to be 2'b00. PHY will automatically switch correct clock selection internally while m31_HOST_REFCLK_DETECT equals to 1.
  [14:13] RES2 — RES - Reserved This field is reserved and RW - MPHY Configuration.
  [12] TX_DEEP_STALL_EN — TX_DEEP_STALL_EN This field is RW. Change M-TX from STALL power mode into DEEP STALL mode to turn off TX PLL. Protocol Layer should only assert and de-assert this signal when M-TX is in STALL power mode. 0:STALL mode. 1:DEEP STALL mode.
  [11] RX_DEEP_STALL_EN — RX_DEEP_STALL_EN This field is RW. Change M-RX from STALL power mode into DEEP STALL mode to turn off RX CDR. Protocol Layer should only assert and de-assert this signal when M-RX is in STALL power mode. 0:STALL mode. 1:DEEP STALL mode.
  [10:7] RES1 — RES - Reserved This field is reserved and RW - MPHY Configuration.
  [6:0] DEBUG_SEL — DEBUG_SEL This field is RW - Debug signal group selection.
0x1188 P2A_WRAP__CFG_VBP__UFSHCI_REGS_MPHYCFG_VCONTROL
  [31:17] RES2 — RES - Reserved This field is reserved and RW - MPHY Configuration.
  [16] VCONTROL_LA_SA_SEL — VCONTROL_LA_SA_Sel This field is RW - TX amplitude selection in VENDOR control mode.
  [15:12] RES1 — RES - Reserved This field is reserved and RW - MPHY Configuration.
  [11:10] VCONTROL_DEEMP_SEL — VCONTROL_Deemp_Sel This field is RW - TX deemphasis selection in VENDOR control mode.
  [9:0] VCONTROL — VCONTROL This field is RW - VCONTROL test mode selection.
0x118C P2A_WRAP__CFG_VBP__UFSHCI_REGS_MPHY_BIST_CTRLPIN
  [31:0] MPHY_BIST_CTRLPIN — MPHY_BIST_CTRLPIN This field is RW. Control pins for VENDOR control mode. This is only for vendor internal use.
0x1190 P2A_WRAP__CFG_VBP__UFSHCI_REGS_MPHY_SF_WD
  [31:3] RES — RES - Reserved This field is reserved and RW - MPHY Configuration.
  [2] SF_PLL_WATCHDOG_EN_MMIO — SF_PLL_WATCHDOG_EN_mmio This field is RW. Safety related, Enable PLL Watch Dog.
  [1] SF_CDR0_WATCHDOG_EN_MMIO — SF_CDR0_WATCHDOG_EN_mmio This field is RW. Safety related, Enable CDR Watch Dog.
  [0] SF_CDR1_WATCHDOG_EN_MMIO — SF_CDR1_WATCHDOG_EN_mmio This field is RW. Safety related, Enable CDR Watch Dog.
